# PIC32MX470F512H register map
Registers are 32-bit, access not given, reset 0x0 unless marked. A register's access mark holds for its fields unless they carry their own. Offsets are from the block's base; [hi:lo] are bit positions; 'fields as' and 'values as' point back to an identical list.

## TMR3 — TMR3 peripheral
Base 0xBF800A00
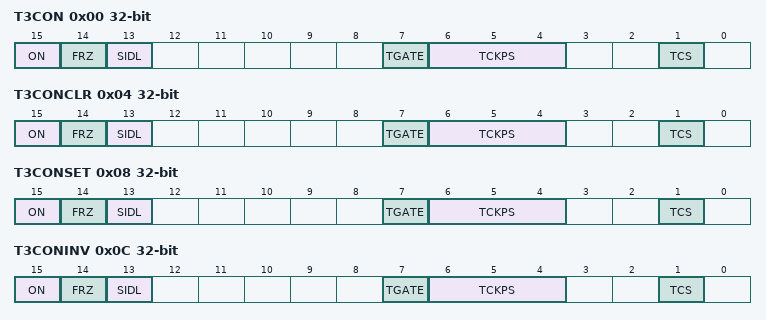
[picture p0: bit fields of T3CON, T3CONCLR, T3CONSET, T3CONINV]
0x00 T3CON
  [15] ON, [14] FRZ, [13] SIDL, [7] TGATE, [6:4] TCKPS, [1] TCS
0x04 T3CONCLR
  [15] ON, [14] FRZ, [13] SIDL, [7] TGATE, [6:4] TCKPS, [1] TCS
0x08 T3CONSET
  [15] ON, [14] FRZ, [13] SIDL, [7] TGATE, [6:4] TCKPS, [1] TCS
0x0C T3CONINV
  [15] ON, [14] FRZ, [13] SIDL, [7] TGATE, [6:4] TCKPS, [1] TCS
0x10 TMR3
0x14 TMR3CLR
  [31:0] TMR3
0x18 TMR3SET
  [31:0] TMR3
0x1C TMR3INV
  [31:0] TMR3
0x20 PR3 reset 0xFFFF
0x24 PR3CLR
  [31:0] PR3
0x28 PR3SET
  [31:0] PR3
0x2C PR3INV
  [31:0] PR3

## TMR4 — TMR4 peripheral
Base 0xBF800C00
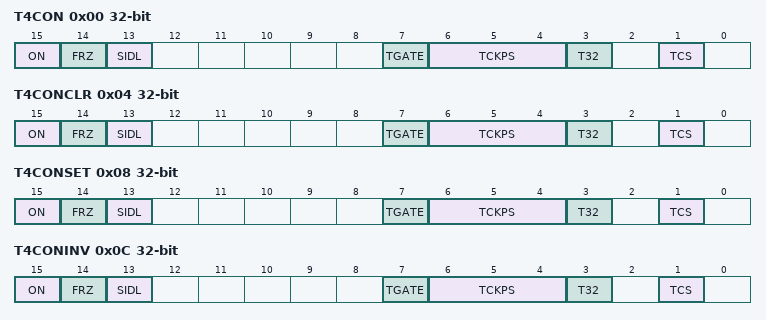
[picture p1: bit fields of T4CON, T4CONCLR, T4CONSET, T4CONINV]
0x00 T4CON
  [15] ON, [14] FRZ, [13] SIDL, [7] TGATE, [6:4] TCKPS, [3] T32, [1] TCS
0x04 T4CONCLR
  fields as T4CON
0x08 T4CONSET
  fields as T4CON
0x0C T4CONINV
  fields as T4CON
0x10 TMR4
0x14 TMR4CLR
  [31:0] TMR4
0x18 TMR4SET
  [31:0] TMR4
0x1C TMR4INV
  [31:0] TMR4
0x20 PR4 reset 0xFFFF
0x24 PR4CLR
  [31:0] PR4
0x28 PR4SET
  [31:0] PR4
0x2C PR4INV
  [31:0] PR4

## TMR5 — TMR5 peripheral
Base 0xBF800E00
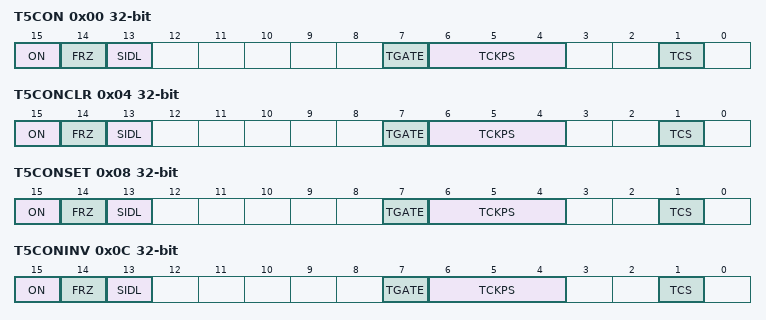
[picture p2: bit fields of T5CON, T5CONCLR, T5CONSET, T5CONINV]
0x00 T5CON
  [15] ON, [14] FRZ, [13] SIDL, [7] TGATE, [6:4] TCKPS, [1] TCS
0x04 T5CONCLR
  [15] ON, [14] FRZ, [13] SIDL, [7] TGATE, [6:4] TCKPS, [1] TCS
0x08 T5CONSET
  [15] ON, [14] FRZ, [13] SIDL, [7] TGATE, [6:4] TCKPS, [1] TCS
0x0C T5CONINV
  [15] ON, [14] FRZ, [13] SIDL, [7] TGATE, [6:4] TCKPS, [1] TCS
0x10 TMR5
0x14 TMR5CLR
  [31:0] TMR5
0x18 TMR5SET
  [31:0] TMR5
0x1C TMR5INV
  [31:0] TMR5
0x20 PR5 reset 0xFFFF
0x24 PR5CLR
  [31:0] PR5
0x28 PR5SET
  [31:0] PR5
0x2C PR5INV
  [31:0] PR5

## ICAP1 — ICAP1 peripheral
Base 0xBF802000
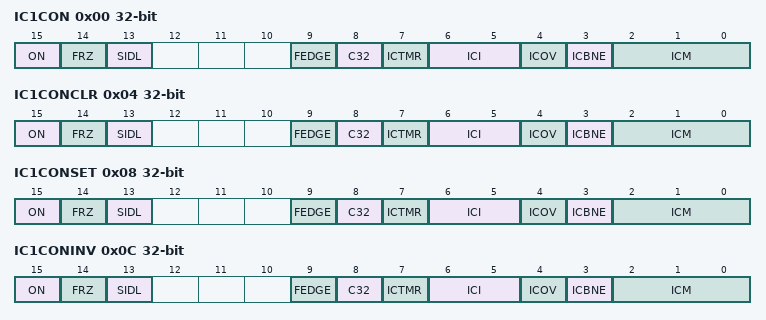
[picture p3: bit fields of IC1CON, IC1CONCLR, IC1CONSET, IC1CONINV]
0x00 IC1CON
  [15] ON, [14] FRZ, [13] SIDL, [9] FEDGE, [8] C32, [7] ICTMR, [6:5] ICI, [4] ICOV, [3] ICBNE, [2:0] ICM
0x04 IC1CONCLR
  fields as IC1CON
0x08 IC1CONSET
  fields as IC1CON
0x0C IC1CONINV
  fields as IC1CON
0x10 IC1BUF

## ICAP2 — ICAP2 peripheral
Base 0xBF802200
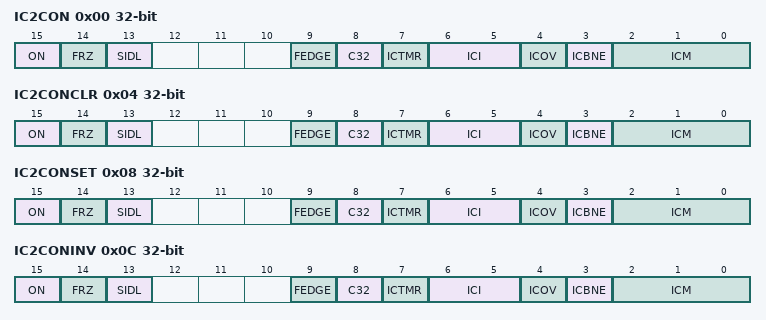
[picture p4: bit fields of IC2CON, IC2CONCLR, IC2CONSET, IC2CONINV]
0x00 IC2CON
  [15] ON, [14] FRZ, [13] SIDL, [9] FEDGE, [8] C32, [7] ICTMR, [6:5] ICI, [4] ICOV, [3] ICBNE, [2:0] ICM
0x04 IC2CONCLR
  fields as IC2CON
0x08 IC2CONSET
  fields as IC2CON
0x0C IC2CONINV
  fields as IC2CON
0x10 IC2BUF

## ICAP3 — ICAP3 peripheral
Base 0xBF802400
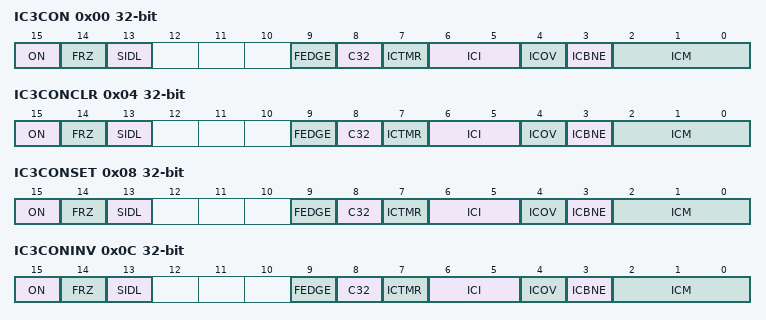
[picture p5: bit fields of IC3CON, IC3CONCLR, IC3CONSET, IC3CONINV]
0x00 IC3CON
  [15] ON, [14] FRZ, [13] SIDL, [9] FEDGE, [8] C32, [7] ICTMR, [6:5] ICI, [4] ICOV, [3] ICBNE, [2:0] ICM
0x04 IC3CONCLR
  fields as IC3CON
0x08 IC3CONSET
  fields as IC3CON
0x0C IC3CONINV
  fields as IC3CON
0x10 IC3BUF

## ICAP4 — ICAP4 peripheral
Base 0xBF802600
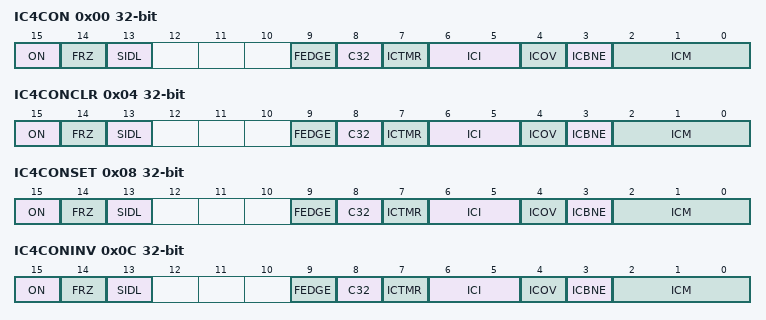
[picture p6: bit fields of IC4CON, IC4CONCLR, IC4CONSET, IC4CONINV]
0x00 IC4CON
  [15] ON, [14] FRZ, [13] SIDL, [9] FEDGE, [8] C32, [7] ICTMR, [6:5] ICI, [4] ICOV, [3] ICBNE, [2:0] ICM
0x04 IC4CONCLR
  fields as IC4CON
0x08 IC4CONSET
  fields as IC4CON
0x0C IC4CONINV
  fields as IC4CON
0x10 IC4BUF

## ICAP5 — ICAP5 peripheral
Base 0xBF802800
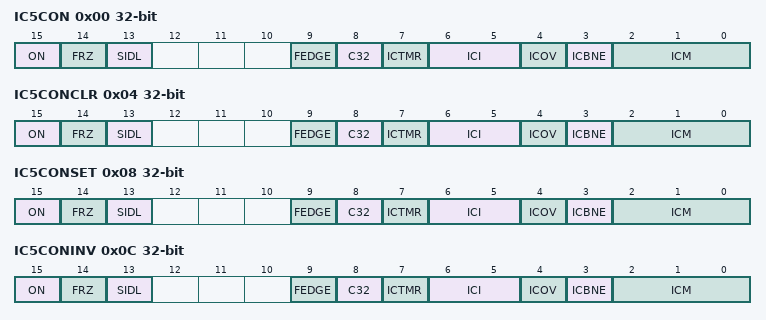
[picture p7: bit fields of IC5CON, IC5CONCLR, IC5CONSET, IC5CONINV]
0x00 IC5CON
  [15] ON, [14] FRZ, [13] SIDL, [9] FEDGE, [8] C32, [7] ICTMR, [6:5] ICI, [4] ICOV, [3] ICBNE, [2:0] ICM
0x04 IC5CONCLR
  fields as IC5CON
0x08 IC5CONSET
  fields as IC5CON
0x0C IC5CONINV
  fields as IC5CON
0x10 IC5BUF

## OCMP1 — OCMP1 peripheral
Base 0xBF803000
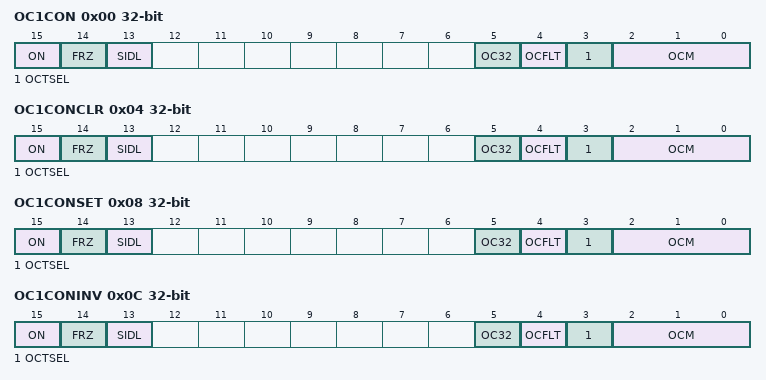
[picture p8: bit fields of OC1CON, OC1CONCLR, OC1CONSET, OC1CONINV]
0x00 OC1CON
  [15] ON, [14] FRZ, [13] SIDL, [5] OC32, [4] OCFLT, [3] OCTSEL, [2:0] OCM
0x04 OC1CONCLR
  fields as OC1CON
0x08 OC1CONSET
  fields as OC1CON
0x0C OC1CONINV
  fields as OC1CON
0x10 OC1R
0x14 OC1RCLR
  [31:0] OC1R
0x18 OC1RSET
  [31:0] OC1R
0x1C OC1RINV
  [31:0] OC1R
0x20 OC1RS
0x24 OC1RSCLR
  [31:0] OC1RS
0x28 OC1RSSET
  [31:0] OC1RS
0x2C OC1RSINV
  [31:0] OC1RS

## OCMP2 — OCMP2 peripheral
Base 0xBF803200
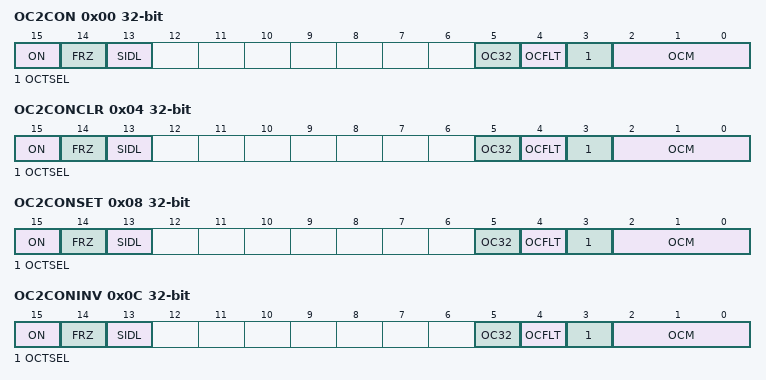
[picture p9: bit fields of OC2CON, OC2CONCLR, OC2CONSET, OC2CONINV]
0x00 OC2CON
  [15] ON, [14] FRZ, [13] SIDL, [5] OC32, [4] OCFLT, [3] OCTSEL, [2:0] OCM
0x04 OC2CONCLR
  fields as OC2CON
0x08 OC2CONSET
  fields as OC2CON
0x0C OC2CONINV
  fields as OC2CON
0x10 OC2R
0x14 OC2RCLR
  [31:0] OC2R
0x18 OC2RSET
  [31:0] OC2R
0x1C OC2RINV
  [31:0] OC2R
0x20 OC2RS
0x24 OC2RSCLR
  [31:0] OC2RS
0x28 OC2RSSET
  [31:0] OC2RS
0x2C OC2RSINV
  [31:0] OC2RS
